# STMP3770 register map
Vendor: Freescale Semiconductor (NXP); Series: STMP37xx; File version: 1.0
CPU: other r0p0, little endian, no MPU, no FPU, 2 interrupt priority bits
Registers are 32-bit, read-write, reset 0x0 unless marked. A register's access mark holds for its fields unless they carry their own. Offsets are from the block's base; [hi:lo] are bit positions; {n}, {i} and the like mark numbered series.

## ECC8 — NAND ECC8/BCH 硬件纠错加速器(配合 GPMI 对 NAND 数据做 ECC 编解码)
Base 0x80008000
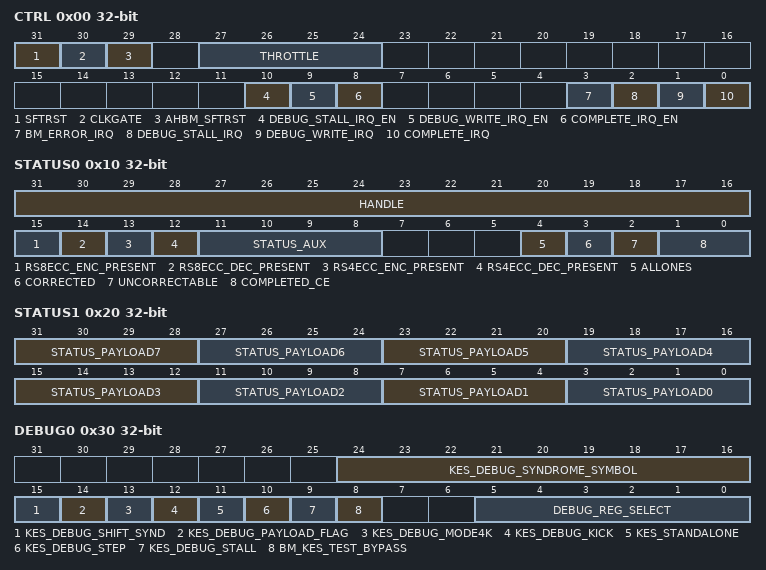
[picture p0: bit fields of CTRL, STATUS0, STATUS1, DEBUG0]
0x00 CTRL — Hardware ECC Accelerator Control Register
  [31] SFTRST — Soft Reset. RW, Reset=0x1. 0=Normal ECC8 operation. 1=Hold ECC8 in reset (lowest power) state. Resets all state machines except AHB master.
    0=RUN; 1=RESET
  [30] CLKGATE — Clock Gate. RW, Reset=0x1. Must be 0 for normal operation. When 1, gates off clocks to minimize power consumption.
    0=RUN; 1=NO_CLKS
  [29] AHBM_SFTRST — AHB Master Soft Reset. RW, Reset=0x1. Resets the AHB state machine. 0=Normal, 1=Reset. Not for normal device soft-resets.
    0=RUN; 1=RESET
  [27:24] THROTTLE — AHB Throttle. RW, Reset=0x0. Non-zero values hold off that number of HCLKs between successive burst requests on AHB.
  [10] DEBUG_STALL_IRQ_EN — Debug Stall Interrupt Enable. RW, Reset=0x0. 1=IRQ on debug stall mode enabled, raised on every block.
  [9] DEBUG_WRITE_IRQ_EN — Debug Write Interrupt Enable. RW, Reset=0x0. 1=IRQ on debug write mode enabled, raised on every transfer. No correction in this mode.
  [8] COMPLETE_IRQ_EN — Complete Interrupt Enable. RW, Reset=0x0. 1=Interrupt on completion of correction is enabled.
  [3] BM_ERROR_IRQ — Bus Master Error IRQ. RW, Reset=0x0. AHB Bus Interface Error Interrupt Status. Write 1 to SCT clear address to clear.
  [2] DEBUG_STALL_IRQ — Debug Stall IRQ. RW, Reset=0x0. Debug Stall Interrupt Status. Write 1 to SCT clear address to clear.
  [1] DEBUG_WRITE_IRQ — Debug Write IRQ. RW, Reset=0x0. Debug Write Interrupt Status. Write 1 to SCT clear address to clear.
  [0] COMPLETE_IRQ — Complete IRQ. RW, Reset=0x0. External Interrupt Line Status. Write 1 to SCT clear address to clear. ECC completions held off while set. Read STATUS0/1 before clearing.
0x10 STATUS0 — Hardware ECC Accelerator Status Register 0
  [31:16] HANDLE — Transfer Handle. RO, Reset=0x0. 16-bit handle from GPMI DMA PIO operation. Passes through pipeline and is present when ECC8 interrupt signals.
  [15] RS8ECC_ENC_PRESENT — RS(8) ECC Encode Present. RO, Reset=0x1. Reserved.
  [14] RS8ECC_DEC_PRESENT — RS(8) ECC Decode Present. RO, Reset=0x1. Reserved.
  [13] RS4ECC_ENC_PRESENT — RS(4) ECC Encode Present. RO, Reset=0x1. Reserved.
  [12] RS4ECC_DEC_PRESENT — RS(4) ECC Decode Present. RO, Reset=0x1. Reserved.
  [11:8] STATUS_AUX — Auxiliary Data Status. RO, Reset=0xC (NOT_CHECKED). Symbol error count for auxiliary area. 0xF=uncorrectable. Values: 0-4=error count, 0xC=not checked, 0xE=uncorrectable, 0xF=all ones.
    0=NO_ERRORS; 1=ONE_CORRECTABLE; 2=TWO_CORRECTABLE; 3=THREE_CORRECTABLE; 4=FOUR_CORRECTABLE; 12=NOT_CHECKED; 14=UNCORRECTABLE; 15=ALL_ONES
  [4] ALLONES — All Ones Flag. RO, Reset=0x1. 1=All data bits of this transaction are 1.
  [3] CORRECTED — Corrected Flag. RO, Reset=0x0. 1=At least one correctable error during last processing cycle.
  [2] UNCORRECTABLE — Uncorrectable Flag. RO, Reset=0x0. 1=Uncorrectable error during last processing cycle.
  [1:0] COMPLETED_CE — Completed Chip Enable. RO, Reset=0x0. Chip enable number (0-3) for the NAND device the data came from.
0x20 STATUS1 — Hardware ECC Accelerator Status Register 1
  [all] fields
    0=NO_ERRORS; 1=ONE_CORRECTABLE; 2=TWO_CORRECTABLE; 3=THREE_CORRECTABLE; 4=FOUR_CORRECTABLE; 5=FIVE_CORRECTABLE; 6=SIX_CORRECTABLE; 7=SEVEN_CORRECTABLE; 8=EIGHT_CORRECTABLE; 12=NOT_CHECKED; 14=UNCORRECTABLE; 15=ALL_ONES
  [31:28] STATUS_PAYLOAD7 — Payload Area 7 Status. RO, Reset=0xC. Symbol error count for payload 7. 0xF=uncorrectable. Values: 0-8=error count, 0xC=not checked, 0xE=uncorrectable, 0xF=all ones.
  [4n+3:4n] STATUS_PAYLOAD{n} (n=0..6) — Payload Area {n} Status. RO, Reset=0xC. Same encoding as STATUS_PAYLOAD7.
0x30 DEBUG0 ro — Hardware ECC Accelerator Debug Register 0
  [24:16] KES_DEBUG_SYNDROME_SYMBOL — KES Debug Syndrome Symbol. RW, Reset=0x0. 9-bit value shifted into syndrome register array at KES input when KES_DEBUG_SHIFT_SYND toggles.
    0=NORMAL; 1=TEST_MODE
  [15] KES_DEBUG_SHIFT_SYND — KES Debug Shift Syndrome. RW, Reset=0x0. Toggling shifts KES_SYNDROME_SYMBOL into syndrome array. After 16 symbols, kick KES/CF by toggling KES_DEBUG_KICK.
  [14] KES_DEBUG_PAYLOAD_FLAG — KES Debug Payload Flag. RW, Reset=0x0. Presented to KES as input payload flag. DATA(1)=512B block. AUX(1)=65/19B auxiliary block.
    1=DATA
  [13] KES_DEBUG_MODE4K — KES Debug 4K Mode. RW, Reset=0x0. Presented to KES as input mode. 4k(1)=4K NAND pages. 2k(1)=2K NAND pages.
    1=_4k
  [12] KES_DEBUG_KICK — KES Debug Kick. RW, Reset=0x0. Toggling starts KES engine FSM as if kicked by bus master for standalone testing.
  [11] KES_STANDALONE — KES Standalone Mode. RW, Reset=0x0. Set to 1 to suppress KES_BM_DONE and CF_BM_DONE signal toggling to bus master.
    0=NORMAL; 1=TEST_MODE
  [10] KES_DEBUG_STEP — KES Debug Step. RW, Reset=0x0. Toggling skips KES FSM past stall state when in DEBUG_STALL mode and block done.
  [9] KES_DEBUG_STALL — KES Debug Stall. RW, Reset=0x0. Stall KES FSM after notifying Chien search but before notifying bus master. 0=proceed, 1=wait.
    0=NORMAL; 1=WAIT
  [8] BM_KES_TEST_BYPASS — Bus Master KES Test Bypass. RW, Reset=0x0. 1=Point synd_gen writes to dummy area for diagnostic preload of payload, parity, syndrome bytes.
    0=NORMAL; 1=TEST_MODE
  [5:0] DEBUG_REG_SELECT — Debug Register Select. RW, Reset=0x0. Selects internal register state view of KES or Chien search engine.
0x40 DBGKESREAD — KES Debug Read Register
  [31:0] VALUES — Debug KES Read Values. RO, Reset=0x0. Reserved.
0x50 DBGCSFEREAD — Chien Search Forney Evaluator Debug Read Register
  [31:0] VALUES — Debug CSFE Read Values. RO, Reset=0x0. Reserved.
0x60 DBGSYNDGENREAD — Syndrome Generator Debug Read Register
  [31:0] VALUES — Debug Syndrome Generator Read Values. RO, Reset=0x0. Reserved.
0x70 DBGAHBMREAD — AHB Master and ECC8 Controller Debug Read Register
  [31:0] VALUES — Debug AHB Master Read Values. RO, Reset=0x0. Reserved.
0x80 BLOCKNAME — ECC8 Block Name Register
  [31:0] NAME — Block Name. RO, Reset=0x38434345. ASCII '8','C','C','E' (ECC8). Readable as zero-terminated ASCII string.
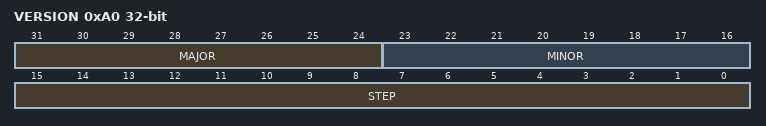
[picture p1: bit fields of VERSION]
0xA0 VERSION ro — ECC8 Version Register
  [31:24] MAJOR — Version Major. RO, Reset=0x01. Fixed read-only MAJOR field of the RTL version.
  [23:16] MINOR — Version Minor. RO, Reset=0x00. Fixed read-only MINOR field of the RTL version.
  [15:0] STEP — Version Step. RO, Reset=0x0000. Fixed read-only stepping field of the RTL version.
